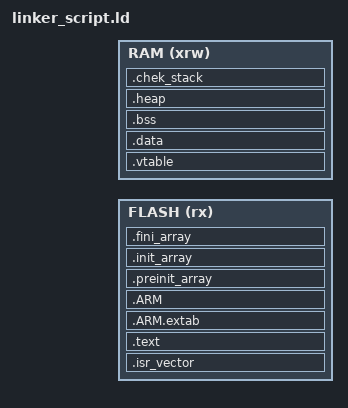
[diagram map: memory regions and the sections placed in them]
/*
The MIT License (MIT)

Copyright (c) 2013 r-3-t

Permission is hereby granted, free of charge, to any person obtaining a copy of
this software and associated documentation files (the "Software"), to deal in
the Software without restriction, including without limitation the rights to
use, copy, modify, merge, publish, distribute, sublicense, and/or sell copies of
the Software, and to permit persons to whom the Software is furnished to do so,
subject to the following conditions:

The above copyright notice and this permission notice shall be included in all
copies or substantial portions of the Software.

THE SOFTWARE IS PROVIDED "AS IS", WITHOUT WARRANTY OF ANY KIND, EXPRESS OR
IMPLIED, INCLUDING BUT NOT LIMITED TO THE WARRANTIES OF MERCHANTABILITY, FITNESS
FOR A PARTICULAR PURPOSE AND NONINFRINGEMENT. IN NO EVENT SHALL THE AUTHORS OR
COPYRIGHT HOLDERS BE LIABLE FOR ANY CLAIM, DAMAGES OR OTHER LIABILITY, WHETHER
IN AN ACTION OF CONTRACT, TORT OR OTHERWISE, ARISING FROM, OUT OF OR IN
CONNECTION WITH THE SOFTWARE OR THE USE OR OTHER DEALINGS IN THE SOFTWARE.
*/

/* Entry Point */
ENTRY(Reset_Handler)

_ram_size = @_RAM_SIZE@;    /* RAM on AHB bus*/

/* Generate a link error if heap and stack don't fit into RAM */
_Min_Heap_Size = @_MIN_HEAP_SIZE@;      /* required amount of heap  */
_Min_Stack_Size = @_MIN_STACK_SIZE@; /* required amount of stack */

/* Specify the memory areas */
MEMORY
{
  FLASH (rx)      : ORIGIN = @_FLASH_ORIGIN@, LENGTH = @_FLASH_SIZE@
  @EXTRAM_MEMORY_AREA@
  RAM (xrw)       : ORIGIN = @_RAM_ORIGIN@, LENGTH = @_RAM_SIZE@
}

/* Highest address of the user mode stack */
_estack = ORIGIN(RAM) + LENGTH(RAM);

/* Define output sections */
SECTIONS
{
  /* The startup code goes first into FLASH */
  .isr_vector :
  {
    . = ALIGN(4);
    KEEP(*(.isr_vector)) /* Startup code */
    . = ALIGN(4);
  } >FLASH

  /* Next, put code */
  .text :
  {
    . = ALIGN(4);
    *(.text)           /* .text sections (code) */
    *(.text*)          /* .text* sections (code) */
    *(.rodata)         /* .rodata sections (constants, strings, etc.) */
    *(.rodata*)        /* .rodata* sections (constants, strings, etc.) */
    *(.glue_7)         /* glue arm to thumb code */
    *(.glue_7t)        /* glue thumb to arm code */

    KEEP (*(.init))
    KEEP (*(.fini))

    . = ALIGN(4);
    _etext = .;        /* define a global symbols at end of code */
  } >FLASH


   .ARM.extab   : { *(.ARM.extab* .gnu.linkonce.armextab.*) } >FLASH
    .ARM : {
    __exidx_start = .;
      *(.ARM.exidx*)
      __exidx_end = .;
    } >FLASH

  .ARM.attributes 0 : { *(.ARM.attributes) }

  .preinit_array     :
  {
    PROVIDE_HIDDEN (__preinit_array_start = .);
    KEEP (*(.preinit_array*))
    PROVIDE_HIDDEN (__preinit_array_end = .);
  } >FLASH
  .init_array :
  {
    PROVIDE_HIDDEN (__init_array_start = .);
    KEEP (*(SORT(.init_array.*)))
    KEEP (*(.init_array*))
    PROVIDE_HIDDEN (__init_array_end = .);
  } >FLASH
  .fini_array :
  {
    PROVIDE_HIDDEN (__fini_array_start = .);
    KEEP (*(.fini_array*))
    KEEP (*(SORT(.fini_array.*)))
    PROVIDE_HIDDEN (__fini_array_end = .);
  } >FLASH

  /* used by the startup to initialize data */
  _sidata = .;

  @EXTRAM_MEMORY_SECTION@

  /* place vector table at the begining of RAM */
  .vtable (NOLOAD):
  {
		*(vtable)           /* vtable sections */
		*(vtable*)          /* vtable* sections */
		. = ALIGN(4);
  } >RAM


  /* Initialized data sections goes into RAM, load LMA copy after code */
  .data : AT ( _sidata )
  {
    . = ALIGN(4);
    _sdata = .;        /* create a global symbol at data start */
    *(.data)           /* .data sections */
    *(.data*)          /* .data* sections */

    . = ALIGN(4);
    _edata = .;        /* define a global symbol at data end */
  } >RAM

  /* Uninitialized data section */
  . = ALIGN(4);
  .bss :
  {
    /* This is used by the startup in order to initialize the .bss secion */
    _sbss = .;         /* define a global symbol at bss start */
    __bss_start__ = _sbss;
    *(.bss)
    *(.bss*)
    *(COMMON)

    . = ALIGN(4);
    _ebss = .;         /* define a global symbol at bss end */
    __bss_end__ = _ebss;
  } >RAM

  PROVIDE ( end = _ebss );
  PROVIDE ( _end = _ebss );

  /* User_heap section, used to check that there is enough RAM left */
  .heap (NOLOAD):
   {
     _heap = . ;
     . = . + _Min_Heap_Size;  /* define _Heap_Size at the start of the link file */
     . = ALIGN(4);
     _heap_end = . ;
   } > RAM

  /*  stack section, used to check that there is enough RAM left */
  .chek_stack (NOLOAD):
  {
    . = ALIGN(4);
    . += _Min_Stack_Size;
    . = ALIGN(4);
   _ram_required = .;
  } >RAM

  /* Remove information from the standard libraries */
  /DISCARD/ :
  {
    libc.a ( * )
    libm.a ( * )
    libgcc.a ( * )
  }
}
